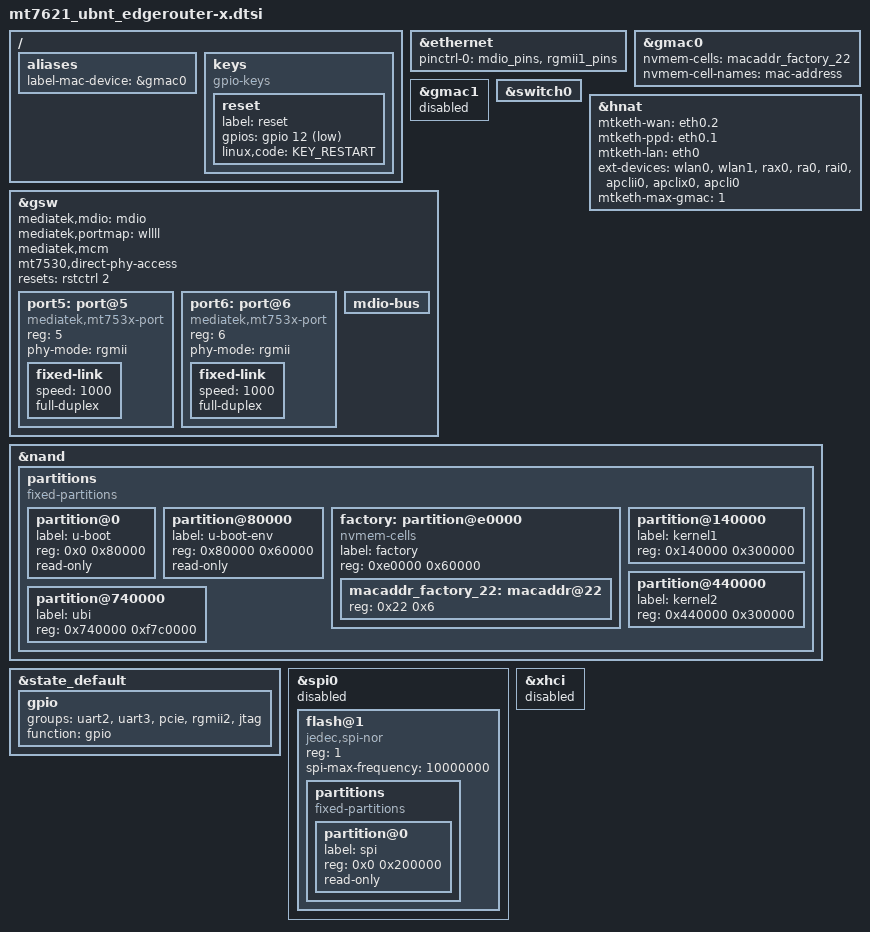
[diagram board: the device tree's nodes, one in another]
#include "mt7621.dtsi"

#include <dt-bindings/gpio/gpio.h>
#include <dt-bindings/input/input.h>

/ {
	aliases {
		label-mac-device = &gmac0;
	};

	keys {
		compatible = "gpio-keys";

		reset {
			label = "reset";
			gpios = <&gpio 12 GPIO_ACTIVE_LOW>;
			linux,code = <KEY_RESTART>;
		};
	};
};

&ethernet {
 	pinctrl-0 = <&mdio_pins>, <&rgmii1_pins>;
 };

&gmac0 {
	nvmem-cells = <&macaddr_factory_22>;
	nvmem-cell-names = "mac-address";
};

&gmac1 {
	status = "disabled";
};

&switch0 {
	/* must delete compatible property */
	/delete-property/ compatible;
};

&hnat {
        mtketh-wan = "eth0.2";
        mtketh-ppd = "eth0.1";
        mtketh-lan = "eth0";
	ext-devices = "wlan0","wlan1","rax0","ra0", "rai0","apclii0","apclix0", "apcli0";
        mtketh-max-gmac = <1>;
        status = "okay";
};

&gsw {
	mediatek,mdio = <&mdio>;
	mediatek,portmap = "wllll";
	mediatek,mcm;
	mt7530,direct-phy-access;

	resets = <&rstctrl 2>;
	reset-names = "mcm";

	port5: port@5 {
		compatible = "mediatek,mt753x-port";
		reg = <5>;
		phy-mode = "rgmii";
		fixed-link {
			speed = <1000>;
			full-duplex;
		};
	};

	port6: port@6 {
		compatible = "mediatek,mt753x-port";
		reg = <6>;
		phy-mode = "rgmii";
		fixed-link {
			speed = <1000>;
			full-duplex;
		};
	};

	mdio-bus {
		#address-cells = <1>;
		#size-cells = <0>;
	};
};


&nand {
	status = "okay";

	partitions {
		compatible = "fixed-partitions";
		#address-cells = <1>;
		#size-cells = <1>;

		partition@0 {
			label = "u-boot";
			reg = <0x0 0x80000>;
			read-only;
		};

		partition@80000 {
			label = "u-boot-env";
			reg = <0x80000 0x60000>;
			read-only;
		};

		factory: partition@e0000 {
			label = "factory";
			reg = <0xe0000 0x60000>;
		};

		partition@140000 {
			label = "kernel1";
			reg = <0x140000 0x300000>;
		};

		partition@440000 {
			label = "kernel2";
			reg = <0x440000 0x300000>;
		};

		partition@740000 {
			label = "ubi";
			reg = <0x740000 0xf7c0000>;
		};
	};
};

&state_default {
	gpio {
		groups = "uart2", "uart3", "pcie", "rgmii2", "jtag";
		function = "gpio";
	};
};

&spi0 {
	/*
	 * This board has 2Mb spi flash soldered in and visible
	 * from manufacturer's firmware.
	 * But this SoC shares spi and nand pins,
	 * and current driver doesn't handle this sharing well
	 */
	status = "disabled";

	flash@1 {
		compatible = "jedec,spi-nor";
		reg = <1>;
		spi-max-frequency = <10000000>;

		partitions {
			compatible = "fixed-partitions";
			#address-cells = <1>;
			#size-cells = <1>;

			partition@0 {
				label = "spi";
				reg = <0x0 0x200000>;
				read-only;
			};
		};
	};
};

&xhci {
	status = "disabled";
};

&factory {
	compatible = "nvmem-cells";
	#address-cells = <1>;
	#size-cells = <1>;

	macaddr_factory_22: macaddr@22 {
		reg = <0x22 0x6>;
	};
};
